# DISPC_L4_PER register map
Vendor: Texas Instruments
Registers are 32-bit, access per field, reset 0x0 unless marked. A register's access mark holds for its fields unless they carry their own. Offsets are as the file gives them; [hi:lo] are bit positions; 'fields as' and 'values as' point back to an identical list.

## DISPC_L4_PER (part 2 of 5)
0x00 DISPC_REVISION ro reset not defined — IP Revision
  [31:0] REVISION — IP revision
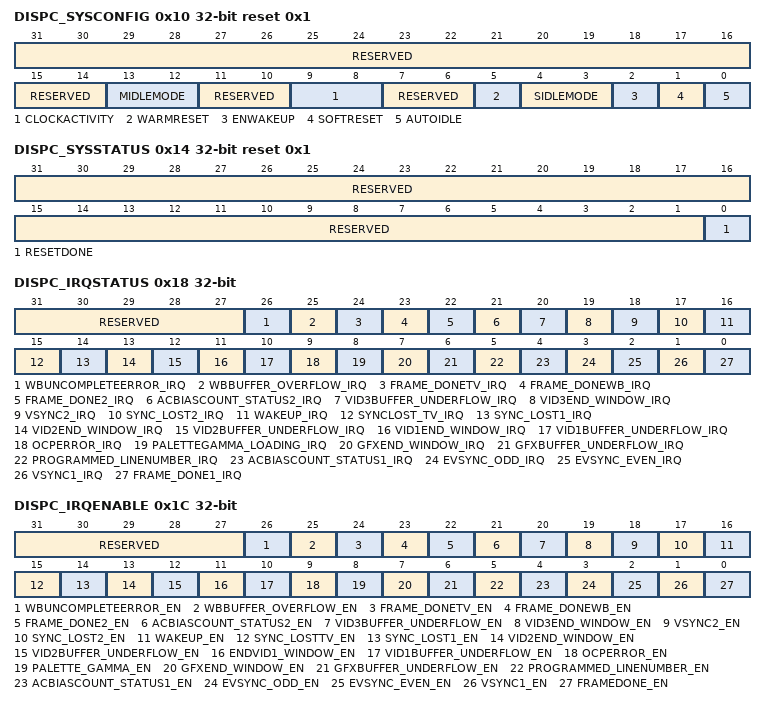
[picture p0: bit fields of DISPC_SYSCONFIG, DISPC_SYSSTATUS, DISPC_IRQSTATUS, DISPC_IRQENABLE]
0x10 DISPC_SYSCONFIG reset 0x1 — This register allows to control various parameters of the OCP interface.
  [31:14] RESERVED ro — Write 0s for future compatibility. Reads returns 0
  [13:12] MIDLEMODE rw — Master interface power management, standby/wait control
    0=Force-standby. MStandby is only asserted when the module is disabled. MStandby is only asserted when the module is disabled.; 1=No-Standby: MStandby is never asserted; 2=Smart-Standby. MStandby is asserted based on the internal activity of the module
  [11:10] RESERVED ro — Write 0s for future compatibility. Reads returns 0
  [9:8] CLOCKACTIVITY rw — Clocks activity during wake up mode period
    0=OCP and Functional clocks can be switched off; 1=Functional clocks can be switched off and OCP clocks are maintained during wake up period; 2=OCP clocks can be switched off and Functional clocks are maintained during wake up period; 3=OCP and Functional clocks are maintained during wake up period
  [7:6] RESERVED ro — Write 0s for future compatibility. Reads returns 0
  [5] WARMRESET rw — Warm reset. Set this bit to 1 triggers a module warm reset. The bit is automatically reset by the hardware. During reads, it always returns 0. The warm reset keep the configuration registers unchanged.
    0=Normal mode; 1=the warmreset is set
  [4:3] SIDLEMODE rw — Slave interface power management, Idle req/ack control
    0=Force-idle. An idle request is acknowledged unconditionally; 1=No-idle. An idle request is never acknowledged; 2=Smart-idle. Acknowledgment to an idle request is given based on the internal activity of the module.
  [2] ENWAKEUP rw — WakeUp feature control
    0=Wakeup is disabled; 1=Wakeup is enabled
  [1] SOFTRESET rw — Software reset. Set this bit to 1 to trigger a module reset. The bit is automatically reset by the hardware. During reads, it always returns 0.
    0=Normal mode; 1=The module is reset
  [0] AUTOIDLE rw — Internal OCP clock gating strategy
    0=OCP clock is free-running; 1=Automatic OCP L3 and L4 clocks gating strategy is applied, based on the OCP interface activity. Automatic functional clock gating is also applied to the functional clock based on the module activity (for instance DISPC_<pipe>_ATTRIBUTES.ENABLE)
0x14 DISPC_SYSSTATUS ro reset 0x1 — This register provides status information about the module, excluding the interrupt status information.
  [31:1] RESERVED — Write 0s for future compatibility. Reads return 0.
  [0] RESETDONE — Internal reset monitoring
    0=RESETDONE_0_r (Internal module reset is on-going); 1=RESETDONE_1_r (Reset completed)
0x18 DISPC_IRQSTATUS access not given — This register regroups all the status of the module internal events that generate an interrupt. Write 1 to a given bit resets this bit
  [31:27] RESERVED ro — Write 0s for future compatibility. Reads returns 0
  [26] WBUNCOMPLETEERROR_IRQ — Write-back DMA buffer is flushed before it is completely drained. In WB capture mode, if the new frame starts before the WB DMA buffers are fully drained (onto external memory), then the contents of the WB DMA buffers are lost (implying last few pixels/lines are corrupted in the captured frame in memory). This interrupt is an indication of that case and will trigger every frame.0x0 READS: Event is false. . 0x0 WRITES: Status bit unchanged. . 0x1 READS: Event is true (Pending). . 0x1 WRITES: Status bit is reset. . (access RW W1toClr)
  [25] WBBUFFER_OVERFLOW_IRQ — Write-back DMA Buffer Overflow. The DMA buffer is full. (access RW W1toClr)
    0=READS: Event is false. WRITES: Status bit unchanged.; 1=READS: Event is true (pending). WRITES: Status bit is reset.
  [24] FRAME_DONETV_IRQ — Frame Done for the TV. The TV output has been disabled by user. All the data have been sent. (access RW W1toClr)
    values as WBBUFFER_OVERFLOW_IRQ
  [23] FRAME_DONEWB_IRQ — Frame Done for the write-back channel. The write-back channel has output the frame. All the data of the frame have been sent to the memory. There is no pending data inside the DMA engine for the write-back channel to be transferred to memory. It is available only when the write-back pipeline transfers back to memory the output of one of the pipelines. In case of overlay capture, the interrupt is not generated and the user shall use the FrameDone for the corresponding captured output. (access RW W1toClr)
    values as WBBUFFER_OVERFLOW_IRQ
  [22] FRAME_DONE2_IRQ — Frame Done for the secondary LCD. The secondary LCD output has been disabled by user. All the data have been sent. (access RW W1toClr)
    values as WBBUFFER_OVERFLOW_IRQ
  [21] ACBIASCOUNT_STATUS2_IRQ — AC Bias Count Status for the secondary LCD (access RW W1toClr)
    values as WBBUFFER_OVERFLOW_IRQ
  [20] VID3BUFFER_UNDERFLOW_IRQ — Video 3 DMA Buffer Underflow. The DMA buffer is not necessarily empty but required data are not present in the DMA buffer (due to out of order responses) (access RW W1toClr)
    values as WBBUFFER_OVERFLOW_IRQ
  [19] VID3END_WINDOW_IRQ — The end of the video 3 Window has been reached. It is detected by the overlay manager when the full video 3 has been displayed. (access RW W1toClr)
    values as WBBUFFER_OVERFLOW_IRQ
  [18] VSYNC2_IRQ — Vertical Synchronization for the secondary LCD (access RW W1toClr)
    values as WBBUFFER_OVERFLOW_IRQ
  [17] SYNC_LOST2_IRQ — Synchronization Lost on the secondary LCD output. The required data are not output at the correct time due to too short blanking periods or stall of at least one pipelines associated with the secondary LCD output. (access RW W1toClr)
    values as WBBUFFER_OVERFLOW_IRQ
  [16] WAKEUP_IRQ — Wake-up (access RW W1toClr)
    values as WBBUFFER_OVERFLOW_IRQ
  [15] SYNCLOST_TV_IRQ — Synchronization Lost on the TV output. The required data are not output at the correct time due to too short blanking periods or stall of at least one pipelines associated with the TV output. (access RW W1toClr)
    values as WBBUFFER_OVERFLOW_IRQ
  [14] SYNC_LOST1_IRQ — Synchronization Lost on the primary LCD output. The required data are not output at the correct time due to too short blanking periods or stall of at least one pipelines associated with the primary LCD output. (access RW W1toClr)
    values as WBBUFFER_OVERFLOW_IRQ
  [13] VID2END_WINDOW_IRQ — The end of the video 2 Window has been reached. It is detected by the overlay manager when the full video 2 has been displayed. (access RW W1toClr)
    values as WBBUFFER_OVERFLOW_IRQ
  [12] VID2BUFFER_UNDERFLOW_IRQ — Video 2 DMA Buffer Underflow. The DMA buffer is not necessarily empty but required data are not present in the DMA buffer (due to out of order responses) (access RW W1toClr)
    values as WBBUFFER_OVERFLOW_IRQ
  [11] VID1END_WINDOW_IRQ — The end of the video 1 Window has been reached. It is detected by the overlay manager when the full video 1 has been displayed. (access RW W1toClr)
    values as WBBUFFER_OVERFLOW_IRQ
  [10] VID1BUFFER_UNDERFLOW_IRQ — Video 1 DMA Buffer Underflow. The DMA buffer is not necessarily empty but required data are not present in the DMA buffer (due to out of order responses) (access RW W1toClr)
    values as WBBUFFER_OVERFLOW_IRQ
  [9] OCPERROR_IRQ — OCP Error. L3 Interconnect has sent SResp=ERR. (access RW W1toClr)
    values as WBBUFFER_OVERFLOW_IRQ
  [8] PALETTEGAMMA_LOADING_IRQ — Palette Gamma Loading status. The palette used as Color Look Up Table (CLUT) for the graphics BITMAP formats (1-, 2-, 4-, or 4-bpp) or as gamma table for the overlay output for the primary LCD output has been loaded successfully. (access RW W1toClr)
    values as WBBUFFER_OVERFLOW_IRQ
  [7] GFXEND_WINDOW_IRQ — The end of the graphics Window has been reached. It is detected by the overlay manager when the full graphics has been displayed. (access RW W1toClr)
    values as WBBUFFER_OVERFLOW_IRQ
  [6] GFXBUFFER_UNDERFLOW_IRQ — Graphics DMA Buffer Underflow. The DMA buffer is not necessarily empty but required data are not present in the DMA buffer (due to out of order responses) (access RW W1toClr)
    values as WBBUFFER_OVERFLOW_IRQ
  [5] PROGRAMMED_LINENUMBER_IRQ — Programmed Line Number. It indicates that the scan of the primary LCD has reached the programmed user line number. (access RW W1toClr)
    values as WBBUFFER_OVERFLOW_IRQ
  [4] ACBIASCOUNT_STATUS1_IRQ — AC Bias Count Status for the primary LCD (access RW W1toClr)
    values as WBBUFFER_OVERFLOW_IRQ
  [3] EVSYNC_ODD_IRQ — VSYNC for odd field from the TV encoder (VENC or HDMI) (access RW W1toClr)
    values as WBBUFFER_OVERFLOW_IRQ
  [2] EVSYNC_EVEN_IRQ — VSYNC for even field from the TV encoder (VENC or HDMI) (access RW W1toClr)
    values as WBBUFFER_OVERFLOW_IRQ
  [1] VSYNC1_IRQ — Vertical Synchronization for the primary LCD. (access RW W1toClr)
    values as WBBUFFER_OVERFLOW_IRQ
  [0] FRAME_DONE1_IRQ — Frame Done for the primary LCD. The primary LCD output has been disabled by user. All the data have been sent. (access RW W1toClr)
    values as WBBUFFER_OVERFLOW_IRQ
0x1C DISPC_IRQENABLE — This register allows to mask/unmask the module internal sources of interrupt, on an event-by-event basis
  [31:27] RESERVED ro — Write 0s for future compatibility. Reads returns 0
  [26] WBUNCOMPLETEERROR_EN rw — The write back buffer has been flushed before it has been fully drained. Enable.
    0=Interrupt is masked; 1=Interrupt is enabled
  [25] WBBUFFER_OVERFLOW_EN rw — Write-back DMA Buffer Overflow. The DMA buffer is full
    0=WBBufferOverflow is masked; 1=WBBufferOverflow generates an interrupt when it occurs
  [24] FRAME_DONETV_EN rw — Frame Done for the TV. The TV output has been disabled by user. All the data have been sent.
    0=Frame Done for the TV output is masked; 1=Frame Done for the TV output generates an interrupt when it occurs
  [23] FRAME_DONEWB_EN rw — Frame Done for the write-back channel. The write-back channel has output the frame. All the data have been sent for the frame have been sent to the memory. There is no pending data inside the DMA engine for the write-back channel to be transferred to memory.
    0=Frame Done for the write-back is masked; 1=Frame Done for the write-back generates an interrupt when it occurs
  [22] FRAME_DONE2_EN rw — Frame Done for the secondary LCD. The secondary LCD output has been disabled by user. All the data have been sent.
    0=Frame Done for the secondary LCD is masked; 1=Frame Done for the secondary LCD generates an interrupt when it occurs
  [21] ACBIASCOUNT_STATUS2_EN rw — AC Bias Count Status for the secondary LCD
    0=ACBiasCountStatus for the secondary LCD output is masked; 1=ACBiasCountStatus for the secondary LCD output generates an interrupt when it occurs
  [20] VID3BUFFER_UNDERFLOW_EN rw — Video 3 DMA Buffer Underflow. The DMA buffer is not necessary empty but required data are not present in the DMA buffer (due to out of order responses)
    0=Vid3BufferUnderflow is masked; 1=Vid3BufferUnderflow generates an interrupt when it occurs
  [19] VID3END_WINDOW_EN rw — The end of the video 3 Window has been reached. It is detected by the overlay manager when the full video 3 has been displayed.
    0=Vid3EndWindow is masked; 1=Vid3EndWindow generates an interrupt when it occurs
  [18] VSYNC2_EN rw — Vertical Synchronization for the secondary LCD
    0=VSYNC for the secondary LCD output is masked; 1=VSYNC for the secondary LCD output generates an interrupt when it occurs
  [17] SYNC_LOST2_EN rw — Synchronization Lost on the secondary LCD output. The required data are not output at the correct time due to too short blanking periods or stall of at least one pipelines associated with the secondary LCD output.
    0=Synchronization Lost on the secondary LCD output is masked; 1=Synchronization Lost on the secondary LCD output generates an interrupt when it occurs
  [16] WAKEUP_EN rw — Wake Up Mask
    0=WakeUp is masked; 1=WakeUp generates an interrupt when it occurs
  [15] SYNC_LOSTTV_EN rw — Synchronization Lost on the TV output. The required data are not output at the correct time due to too short blanking periods or stall of at least one pipelines associated with the TV output.
    0=Synchronization Lost on the TV output is masked; 1=Synchronization Lost on the TV output generates an interrupt when it occurs
  [14] SYNC_LOST1_EN rw — Synchronization Lost for the primary LCD
    0=SyncLost for the primary LCD output is masked; 1=SyncLost for the primary LCD output generates an interrupt when it occurs
  [13] VID2END_WINDOW_EN rw — The end of the video 2 Window has been reached. It is detected by the overlay manager when the full video 2 has been displayed.
    0=Vid2EndWindow is masked; 1=Vid2EndWindow generates an interrupt when it occurs
  [12] VID2BUFFER_UNDERFLOW_EN rw — Video 2 DMA Buffer Underflow. The DMA buffer is not necessary empty but required data are not present in the DMA buffer (due to out of order responses)
    0=Vid2BufferUnderflow is masked; 1=Vid2BufferUnderflow generates an interrupt when it occurs
  [11] ENDVID1_WINDOW_EN rw — The end of the video 1 Window has been reached. It is detected by the overlay manager when the full video 1 has been displayed.
    0=EndVid1Window is masked; 1=EndVid1Window generates an interrupt when it occurs
  [10] VID1BUFFER_UNDERFLOW_EN rw — Video 1 DMA Buffer Underflow. The DMA buffer is not necessary empty but required data are not present in the DMA buffer (due to out of order responses)
    0=Vid1BufferUnderflow is masked; 1=Vid1BufferUnderflow generates an interrupt when it occurs
  [9] OCPERROR_EN rw — OCP Error. L3 Interconnect has sent SResp=ERR.
    0=OCPError is masked; 1=OCPError generates an interrupt when it occurs
  [8] PALETTE_GAMMA_EN rw — Palette Gamma Loading mask. The palette used as Color Look Up Table (CLUT) for the graphics BITMAP formats (1-, 2-, 4-, or 4-bpp) or as gamma table for the overlay output for the primary LCD output has been loaded successfully.
    0=PaletteGamma is masked; 1=PaletteGamma generates an interrupt when it occurs
  [7] GFXEND_WINDOW_EN rw — The end of the graphics Window has been reached. It is detected by the overlay manager when the full graphics has been displayed.
    0=GfxEndWindow is masked; 1=GfxEndWindow generates an interrupt when it occurs
  [6] GFXBUFFER_UNDERFLOW_EN rw — Graphics DMA Buffer Underflow. The DMA buffer is not necessarily empty but required data are not present in the DMA buffer (due to out of order responses)
    0=GfxBufferUnderflow is masked; 1=GfxBufferUnderflow generates an interrupt when it occurs
  [5] PROGRAMMED_LINENUMBER_EN rw — Programmed Line Number. It indicates that the scan of the primary LCD has reached the programmed user line number.
    0=ProgrammedLineNumber is masked; 1=ProgrammedLineNumber generates an interrupt when it occurs
  [4] ACBIASCOUNT_STATUS1_EN rw — AC Bias Count Status for the primary LCD
    0=ACBiasCountStatus for the primary LCD output is masked; 1=ACBiasCountStatus for the primary LCD output generates an interrupt when it occurs
  [3] EVSYNC_ODD_EN rw — VSYNC for odd field from the TV encoder (VENC or HDMI)
    0=EVSYNC_ODD for the TV output is masked; 1=EVSYNC_ODD for the TV output generates an interrupt when it occurs
  [2] EVSYNC_EVEN_EN rw — VSYNC for even field from the TV encoder (VENC or HDMI)
    0=EVSYNC_EVEN for the TV output is masked; 1=EVSYNC_EVEN for the TV output generates an interrupt when it occurs
  [1] VSYNC1_EN rw — Vertical Synchronization for the primary LCD.
    0=VSYNC for the primary LCD output is masked; 1=VSYNC for the primary LCD output generates an interrupt when it occurs
  [0] FRAMEDONE_EN rw — Frame Done for the primary LCD. The primary LCD output has been disabled by user. All the data have been sent.
    0=FrameDone for the primary LCD output is masked; 1=FrameDone for the primary LCD output generates an interrupt when it occurs
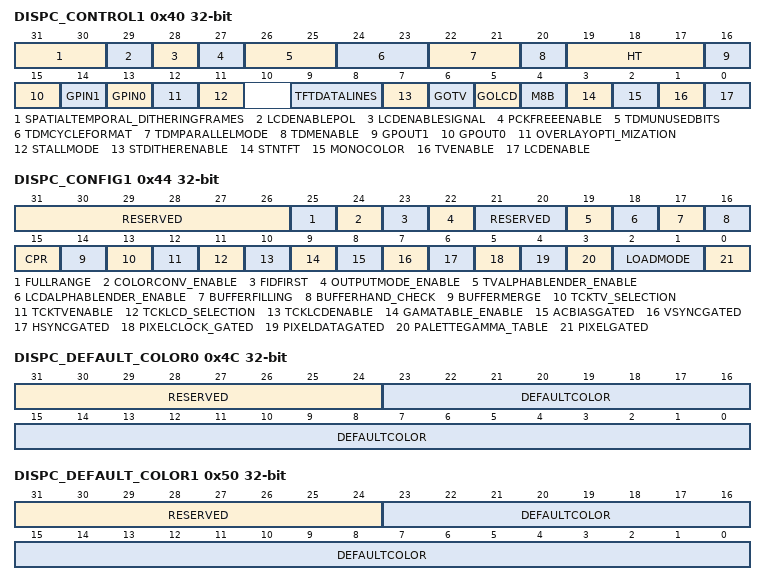
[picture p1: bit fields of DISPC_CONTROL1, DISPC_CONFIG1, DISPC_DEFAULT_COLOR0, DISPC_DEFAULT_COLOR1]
0x40 DISPC_CONTROL1 — The control register configures the Display Controller module for the primary LCD and TV outputs.
  [31:30] SPATIALTEMPORAL_DITHERINGFRAMES rw — Spatial/Temporal dithering number of frames for the primary LCD output wr: VFP start period of primary LCD
    0=Spatial only; 1=Spatial and temporal over 2 frames; 2=Spatial and temporal over 4 frames
  [29] LCDENABLEPOL ro — Write 0s for future compatibility. Reads return 0.
  [28] LCDENABLESIGNAL ro — Write 0s for future compatibility. Reads return 0.
  [27] PCKFREEENABLE ro — Write 0s for future compatibility. Reads return 0.
  [26:25] TDMUNUSEDBITS rw — State of unused bits (TDM mode only) for the primary LCD output. wr: VFP start period of primary LCD
    0=low level (0); 1=high level (1); 2=unchanged from previous state
  [24:23] TDMCYCLEFORMAT rw — Cycle format (TDM mode only) for the primary LCD output wr: VFP start period of primary LCD
    0=1 cycle for 1 pixel; 1=2 cycles for 1 pixel; 2=3 cycles for 1 pixel; 3=3 cycles for 2 pixels
  [22:21] TDMPARALLELMODE rw — Output Interface width (TDM mode only) for the primary LCD output wr: VFP start period of primary LCD
    0=8-bit parallel output interface selected; 1=9-bit parallel output interface selected; 2=12-bit parallel output interface selected; 3=16-bit parallel output interface selected
  [20] TDMENABLE rw — Enable the multiple cycle format (TDM mode only used for TFT mode with the RFBI enable bit off) for the primary LCD output. wr: VFP start period of primary LCD
    0=TDM disabled; 1=TDM enabled
  [19:17] HT rw — Hold Time for TV output wr: EVSYNC Encoded value (from 1 to 8) to specify the number of external digital clock periods to hold the data (programmed value = value minus 1)
  [16] GPOUT1 rw — General Purpose Output Signal wr:immediate
    0=The GPout1 is reset; 1=The GPout1 is set
  [15] GPOUT0 rw — General Purpose Output Signal wr:immediate
    0=The GPout0 is reset; 1=The GPout0 is set
  [14] GPIN1 ro — General Purpose Input Signal wr: immediately
    0=GPIN1_0_r (The GPin1 has been reset); 1=GPIN1_1_r (The GPin1 has been set)
  [13] GPIN0 ro — General Purpose Input Signal wr: immediately
    0=GPIN0_0_r (The GPin0 has been reset); 1=GPIN0_1_r (The GPin0 has been set)
  [12] OVERLAYOPTI_MIZATION rw — Overlay Optimization for the primary LCD output wr: VFP start period of the primary LCD
    0=All the data for all the enabled pipelines are fetched from memory regardless of the overlay/alpha blending configuration; 1=The data not used by the overlay manager because of overlap between layers with no alpha blending between them shall not be fetched from memory in order to optimize the bandwidth
  [11] STALLMODE rw — STALL Mode for the primary LCD output wr: VFP start period of primary LCD
    0=Normal mode selected; 1=STALL mode selected. The Display Controller sends the data without considering the VSYNC/HSYNC. The LCD output is disabled at the end of the transfer of the frame. The S/W has to re-enable the LCD output in order to generate a new frame. The stall mode is used in RFBI and DSI command modes.
  [9:8] TFTDATALINES rw — Number of lines of the primary LCD interface wr: VFP start period of primary LCD
    0=12-bit output aligned on the LSB of the pixel data interface; 1=16-bit output aligned on the LSB of the pixel data interface; 2=18-bit output aligned on the LSB of the pixel data interface; 3=24-bit output aligned on the LSB of the pixel data interface
  [7] STDITHERENABLE rw — Spatial Temporal dithering enable for the primary LCD output wr: VFP start period of primary LCD
    0=Spatial/Temporal dithering logic disabled; 1=Spatial/Temporal dithering logic enabled
  [6] GOTV rw — GO Command for the TV output. It is used to synchronized the pipelines (graphics and/or video ones) associated with the TV output. wr: immediate
    0=The hardware has finished updating the internal shadow registers of the pipeline(s) associated with the TV output using the user values. The hardware resets the bit when the update is completed.; 1=The user has finished to program the shadow registers of the pipeline(s) associated with the TV output and the hardware can update the internal registers at the external VSYNC
  [5] GOLCD rw — GO Command for the primary LCD output. It is used to synchronized the pipelines (graphics and/or video ones) associated with the primary LCD output. wr: immediate
    0=The hardware has finished updating the internal shadow registers of the pipeline(s) connected to the LCD output using the user values. The hardware resets the bit when the update is completed.; 1=The user has finished to program the shadow registers of the pipeline(s) associated with the LCD output and the hardware can update the internal registers at the VFP start period
  [4] M8B rw — Mono 8-bit mode of the primary LCD wr: VFP start period of primary LCD output
    0=Pixel data [3:0] is used to output four pixel values to the panel at each pixel clock transition. (only in Passive Mono 4-bit mode).; 1=Pixel data [7:0] is used to output eight pixel values to the panel each pixel clock transition. (only in Passive Mono 8-bit mode).
  [3] STNTFT rw — LCD Display type of the primary LCD wr: VFP start period of primary LCD output
    0=Passive or STN display operation enabled. STN dither logic is enabled.; 1=Active or TFT display operation enabled. STN Dither logic and output FIFO bypassed.
  [2] MONOCOLOR rw — Monochrome/Color selection for the primary LCD wr: VFP start period of primary LCD output
    0=Color operation enabled (STN mode only); 1=Monochrome operation enabled (STN mode only)
  [1] TVENABLE rw — Enable the TV output wr: immediate effect only occurs at the end of the current frame.
    0=TV output disabled (at the end of the current field if interlace output when the bit is reset); 1=TV output enabled
  [0] LCDENABLE rw — Enable the primary LCD outputs wr: immediate Effect only occurs at the end of the current frame
    0=LCD output disabled (at the end of the frame when the bit is reset); 1=LCD output enabled
0x44 DISPC_CONFIG1 — The control register configures the Display Controller module for the primary LCD output and TV output. Shadow register, updated on VFP start period of primary LCD or EVSYNC or when.GOWB is set to 1 by software and current WB frame is finished (no more data in the write-back pipeline). The synchronization event is defined based on the output using the pipeline: primary LCD, secondary LCD, TV output or write-back to the memory
  [31:26] RESERVED ro — Write 0s for future compatibility. Reads return 0.
  [25] FULLRANGE rw — Color Space Conversion full range setting. wr: VFP start of primary LCD
    0=Limited range selected; 1=Full range selected
  [24] COLORCONV_ENABLE rw — Enable the color space conversion. It shall be reset when CPR bit field is set to 0x1. wr: VFP start of primary LCD
    0=Disable Color Space Conversion RGB to YUV; 1=Enable Color Space Conversion RGB to YUV
  [23] FIDFIRST rw — Selects the first field to output in case of interlace mode. In case of progressive mode, the value is not used. wr: VFP start of primary LCD
    0=First field is even; 1=Odd field is first
  [22] OUTPUTMODE_ENABLE rw — Selects between progressive and interlace mode for the primary LCD output. wr: VFP start of primary LCD
    0=Progressive mode selected; 1=Interlace mode selected
  [21:20] RESERVED rw — Write 0s for future compatibility. Reads return 0.
  [19] TVALPHABLENDER_ENABLE rw — Selects the alpha blender overlay manager for the TV output instead of the color key alpha blender (LCD output). The bit field is deprecated. It is present for software backward compatibility only. When it is enabled, the Z-order defined in each ATTRIBUTES registers for only the pipelines associated pipeline connected to the TV output are invalid and replaced by the following: graphics z-order = 3, video3 z-order = 2, video2 z-order =1 and video1 z-order=0 If it disabled, the z-order and z-order enable bit fields defined in each ATTRIBUTES register are used. wr: EVSYNC start of primary LCD
    0=Alpha blender is disabled; 1=The alpha blender is enabled
  [18] LCDALPHABLENDER_ENABLE rw — Selects the alpha blender overlay manager for the primary LCD output instead of the color key alpha blender (LCD output). The bit field is deprecated. It is present for software backward compatibility only. When it is enabled, the Z-order defined in each ATTRIBUTES registers for only the pipelines associated with the primary LCD output are invalid and replaced by the following: graphics z-order = 3, video3 z-order = 2, video2 z-order =1 and video1 z-order=0 If it disabled, the z-order and z-order enable bit fields defined in each ATTRIBUTES register are used. wr: VFP start of primary LCD
    0=Alpha blender is disabled. The color key alpha blending is used.; 1=The alpha blender is enabled
  [17] BUFFERFILLING rw — Controls if the DMA buffers are refilled only when the LOW threshold is reached or if all DMA buffers are refilled when at least one of them reaches the LOW threshold. wr: immediate
    0=Each DMA buffer is refilled when it reaches LOW threshold; 1=All DMA buffers are refilled up to high threshold when at least one of them reaches the LOW threshold. (only active DMA buffers shall be considered and when reaching the end of the frame the DMA buffer goes to empty condition so no need to fill it again).
  [16] BUFFERHAND_CHECK rw — Controls the handcheck between DMA buffer and STALL signal in order to prevent from underflow. The bit shall be set to 0 when the module is not in STALL mode. (primary LCD output) wr: VFP start of primary LCD
    0=Only the STALL signal (generated by RFBI, DSI1 or DSI2 depending on which IP uses the LCD output) is used regardless of the DMA buffer fullness information in order to provide data to the RFBI,DSI1 or DS2 module; 1=The STALL signal (generated by RFBI, DSI1 or DSI2 depending on which IP uses the LCD output) is used in combination with the DMA buffer fullness information in order to provide data to the RFBI, DSI1 or DSI2 module only when it does not generated buffer underflow
  [15] CPR rw — Color Phase Rotation Control (primary LCD output). It shall be reset when ColorConvEnable bit field is set to 1 wr: VFP start period of primary LCD output
    0=Color Phase Rotation Disabled; 1=Color Phase Rotation Enabled
  [14] BUFFERMERGE rw — Buffer merge control wr: EVSYNC or whenDISPC_CONTROL2.GOWB is set to 1 by software and current WB frame is finished (no more data in the write-back pipeline). The synchronization event is defined based on the output using the pipeline: primary LCD, secondary LCD, TV output or write-back to the memory or VFP When enabled, the DISPC_GLOBAL_BUFFER register is ignored. This bit must be set to zero when the write back channel is used. When DISPC_CONTROL2.GOWB is used BUFFERMERGE MUST be zero. When DISPC_CONTROL2.GOWB is used BUFFERMERGE MUST be zero. wr: immediate
    0=DMA buffer merge disabled Each DMA buffer is dedicated to one pipeline; 1=DMA buffer merge enabled All the DMA buffers are merged into a single one to be used by the single active pipeline
  [13] TCKTV_SELECTION rw — Transparency Color Key Selection (TV output) wr: EVSYNC
    0=Destination transparency color key selected; 1=Source transparency color key selected
  [12] TCKTVENABLE rw — Transparency Color Key Enabled (TV output) wr: EVSYNC
    0=Disable the transparency color key for the TV output; 1=Enable the transparency color key for the TV output
  [11] TCKLCD_SELECTION rw — Transparency Color Key Selection (primary LCD output) wr: VFP start period of primary LCD output
    values as TCKTV_SELECTION
  [10] TCKLCDENABLE rw — Transparency Color Key Enabled (primary LCD output) wr: VFP start period of primary LCD output
    0=Disable the transparency color key for the LCD; 1=Enable the transparency color key for the LCD
  [9] GAMATABLE_ENABLE rw — For backward compatibility, an enable bit has been added on the 2 additional gamma tables (secondary display and TV). Gamma table of LCD1 is always enabled.
    0=Gamma table LDC2 and TV are bypassed; 1=Gamma table LCD2 and TV are enabled
  [8] ACBIASGATED rw — ACBias Gated Enabled (primary LCD output) wr: VFP start period of primary LCD output
    0=AcBias Gated Disabled; 1=AcBias Gated Enabled
  [7] VSYNCGATED rw — VSYNC Gated Enabled (primary LCD output) wr: VFP start period of primary LCD output
    0=VSYNC Gated Disabled; 1=VSYNC Gated Enabled
  [6] HSYNCGATED rw — HSYNC Gated Enabled (primary LCD output) wr: VFP start period of primary LCD output
    0=HSYNC Gated Disabled; 1=HSYNC Gated Enabled
  [5] PIXELCLOCK_GATED rw — Pixel Clock Gated Enabled (primary LCD output) wr: VFP start period of primary LCD output
    0=Pixel Clock Gated Disabled; 1=Pixel Clock Gated Enabled
  [4] PIXELDATAGATED rw — Pixel Data Gated Enabled (primary LCD output) wr: VFP start period of primary LCD output
    0=Pixel Data Gated Disabled; 1=Pixel Data Gated Enabled
  [3] PALETTEGAMMA_TABLE rw — Palette/Gamma Table selection wr: VFP start period of primary LCD output or VFP start period of secondary LCD output or EVSYNC or whenDISPC_CONTROL2.GOWB is set to 1 by software and current WB frame is finished (no more data in the write-back pipeline). The synchronization event is defined based on the output using the graphics pipeline: primary LCD, secondary LCD, TV output or write-back to the memory. In case of the table is used as gamma table, it is used for the primary LCD output only.
    0=LUT used as palette (only if graphics format is BITMAP1, 2, 4, and 8); 1=LUT used as gamma table (only if graphics format is NOT BITMAP1, 2, 4, and 8 or no graphics window present)
  [2:1] LOADMODE rw — Loading Mode for the Palette/Gamma Table wr: VFP start period of primary LCD output or VFP start period of secondary LCD output or EVSYNC or whenDISPC_CONTROL2.GOWB is set to 1 by software and current WB frame is finished (no more data in the write-back pipeline). The synchronization event is defined based on the output using the pipeline: primary LCD, secondary LCD, TV output or write-back to the memory
    0=Palette/Gamma Table and data are loaded every frame; 1=Palette/Gamma Table to be loaded. The user sets the bit when the palette/gamma table has to be loaded. Hardware resets the bit to 0x2 when table has been loaded. (.ENABLE has to be set to 1).; 2=Frame data only loaded every frame; 3=Palette/Gamma Table and frame data loaded on first frame then switch to 0x2 (Hardware)
  [0] PIXELGATED rw — Pixel Gated Enable (only for TFT) (primary LCD output) wr: VFP start period of primary LCD output
    0=Pixel clock always toggles (only in TFT mode); 1=Pixel clock only toggles when there is valid data to display. (only in TFT mode)
0x4C DISPC_DEFAULT_COLOR0 — The control register allows to configure the default solid background color for the primary LCD. Shadow register, updated on VFP start period of the primary LCD
  [31:24] RESERVED ro — Write 0s for future compatibility. Reads return 0.
  [23:0] DEFAULTCOLOR rw — 24-bit RGB color value to specify the default solid color to display when there is no data from the overlays.
0x50 DISPC_DEFAULT_COLOR1 — The control register allows to configure the default solid background color for the TV output. Shadow register, updated on EVSYNC
  fields as DISPC_DEFAULT_COLOR0
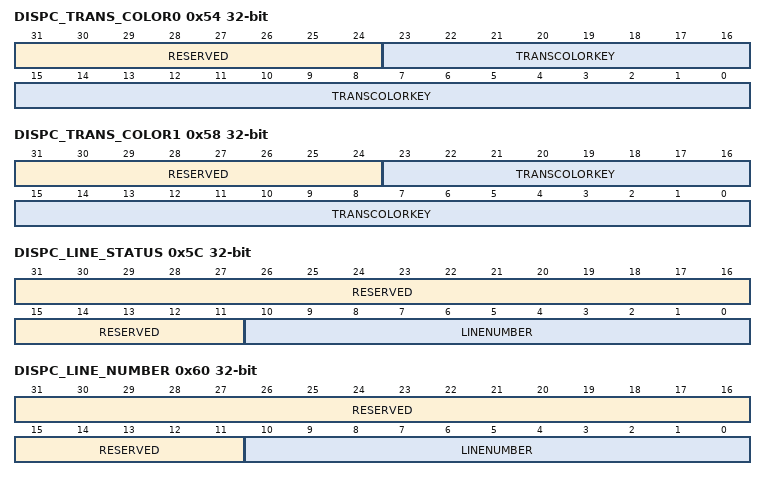
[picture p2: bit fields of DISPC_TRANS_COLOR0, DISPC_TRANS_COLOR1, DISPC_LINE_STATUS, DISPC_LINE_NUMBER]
0x54 DISPC_TRANS_COLOR0 — The register sets the transparency color value for the video/graphics overlays for the primary LCD output. Shadow register, updated on VFP start period of the primary LCD
  [31:24] RESERVED ro — Write 0s for future compatibility. Reads return 0.
  [23:0] TRANSCOLORKEY rw — Transparency Color Key Value in RGB format [0] BITMAP 1 (CLUT), [23,1] set to 0s [1:0] BITMAP 2 (CLUT), [23,2] set to 0s [3:0] BITMAP 4 (CLUT), [23,4] set to 0s [7:0] BITMAP 8 (CLUT), [23,8] set to 0s [11:0] RGB 12, [23,12] set to 0s [15:0] RGB 16, [23,16] set to 0s [23:0] RGB 24
0x58 DISPC_TRANS_COLOR1 — The register sets the transparency color value for the video/graphics overlays for the TV output. Shadow register, updated on EVSYNC
  fields as DISPC_TRANS_COLOR0
0x5C DISPC_LINE_STATUS ro — The control register indicates the current primary LCD panel display line number.
  [31:11] RESERVED — Write 0s for future compatibility. Reads return 0.
  [10:0] LINENUMBER — Current LCD panel line number Current display line number. The first active line has the value 0. During blanking lines the line number is not incremented.
0x60 DISPC_LINE_NUMBER — The control register indicates the primary LCD panel display line number for the interrupt and the DMA request. Shadow register, updated on VFP start period of primary LCD.
  [31:11] RESERVED ro — Write 0s for future compatibility. Reads return 0.
  [10:0] LINENUMBER rw — LCD panel line number programming LCD line number defines the line on which the programmable interrupt is generated and the DMA request occurs.
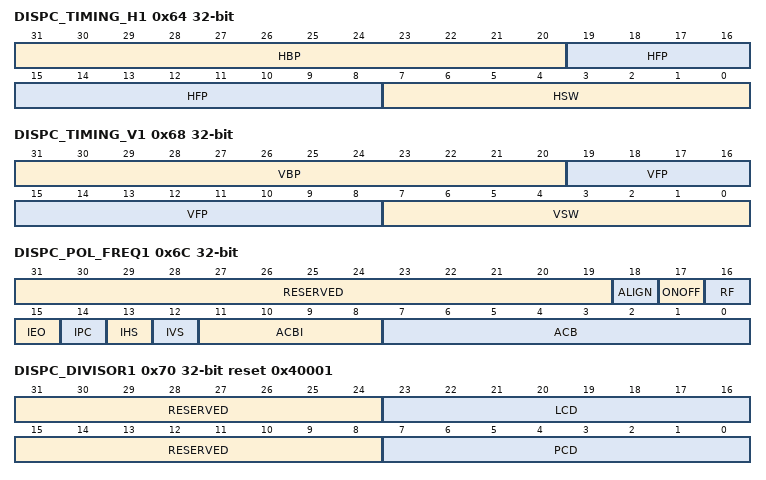
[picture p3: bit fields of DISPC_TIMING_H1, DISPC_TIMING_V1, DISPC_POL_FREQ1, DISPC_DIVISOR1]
0x64 DISPC_TIMING_H1 rw — The register configures the timing logic for the HSYNC signal. It is used for the primary LCD output. Shadow register, updated on VFP start period of primary LCD
  [31:20] HBP — Horizontal Back Porch. Encoded value (from 1 to 4096) to specify the number of pixel clock periods to add to the beginning of a line transmission before the first set of pixels is output to the display (program to value minus 1). When in BT mode and interlaced, this field corresponds to the vertical field blanking No 2 for Even Field.
  [19:8] HFP — Horizontal front porch. Encoded value (from 1 to 4096) to specify the number of pixel clock periods to add to the end of a line transmission before line clock is asserted (program to value minus 1). When in BT mode and interlaced, this field corresponds to the vertical field blanking No 1 for Even Field.
  [7:0] HSW — Horizontal synchronization pulse width Encoded value (from 1 to 256) to specify the number of pixel clock periods to pulse the line clock at the end of each line (program to value minus 1). When in BT mode, this field corresponds to the horizontal blanking
0x68 DISPC_TIMING_V1 rw — The register configures the timing logic for the VSYNC signal. It is used for the primary LCD output. Shadow register, updated on VFP start period of primary LCD
  [31:20] VBP — Vertical back porch Encoded value (from 0 to 4095) to specify the number of line clock periods to add to the beginning of a frame.
  [19:8] VFP — Vertical front porch Encoded value (from 0 to 4095) to specify the number of line clock periods to add to the end of each frame.
  [7:0] VSW — Vertical synchronization pulse width In active mode, encoded value (from 1 to 256) to specify the number of line clock periods (program to value minus 1) to pulse the frame clock (VSYNC) pin at the end of each frame after the end of frame wait (VFP) period elapses. Frame clock uses as VSYNC signal in active mode. In passive mode, encoded value (from 1 to 256) to specify the number of extra line clock periods (program to value minus 1) to insert after the vertical front porch (VFP) period has elapsed.
0x6C DISPC_POL_FREQ1 — The register configures the signal configuration. It is used for the primary LCD output. Shadow register, updated on VFP start period of primary LCD.
  [31:19] RESERVED ro — Write 0s for future compatibility. Reads return 0.
  [18] ALIGN rw — Defines the alignment between HSYNC and VSYNC assertion.
    0=VSYNC and HSYNC are not aligned; 1=VSYNC and HSYNC assertions are aligned
  [17] ONOFF rw — HSYNC/VSYNC Pixel clock Control On/Off
    0=HSYNC and VSYNC are driven on opposite edges of pixel clock than pixel data; 1=HSYNC and VSYNC are driven according to bit 16
  [16] RF rw — Program HSYNC/VSYNC Rise or Fall
    0=HSYNC and VSYNC are driven on falling edge of pixel clock (if bit 17 set to 1); 1=HSYNC and VSYNC are driven on rising edge of pixel clock (if bit 17 set to 1)
  [15] IEO rw — Invert output enable
    0=Ac-bias is active high (active display mode); 1=Ac-bias is active low (active display mode)
  [14] IPC rw — Invert pixel clock
    0=Data is driven on the LCD data lines on the rising-edge of the pixel clock; 1=Data is driven on the LCD data lines on the falling-edge of the pixel clock
  [13] IHS rw — Invert HSYNC
    0=Line clock pin is active high and inactive low; 1=Line clock pin is active low and inactive high
  [12] IVS rw — Invert VSYNC
    0=Frame clock pin is active high and inactive low; 1=Frame clock pin is active low and inactive high
  [11:8] ACBI rw — AC Bias Pin transitions per interrupt Value (from 0 to 15) used to specify the number of AC Bias pin transitions
  [7:0] ACB rw — AC Bias Pin Frequency Value (from 0 to 255) used to specify the number of line clocks to count before transitioning the AC Bias pin. This pin is used to periodically invert the polarity of the power supply to prevent DC charge build-up within the display.
0x70 DISPC_DIVISOR1 reset 0x40001 — The register configures the divisors. It is used for the primary LCD output Shadow register, updated on VFP start period of primary LCD
  [31:24] RESERVED ro — Write 0s for future compatibility. Reads return 0.
  [23:16] LCD rw — Display Controller Logic Clock Divisor Value (from 1 to 255) to specify the intermediate pixel clock frequency based on the LCD1_CLK. The value 0 is invalid.
  [15:8] RESERVED ro — Write 0s for future compatibility. Reads return 0.
  [7:0] PCD rw — Pixel Clock Divisor Value (from 1 to 255) to specify the frequency of the pixel clock based on the LCD1_CLK divided byDISPC_DIVISOR1.LCD value. The values 0 is invalid.
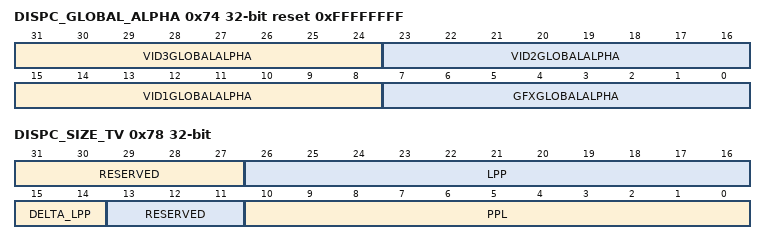
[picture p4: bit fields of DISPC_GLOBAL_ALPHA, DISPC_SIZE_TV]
0x74 DISPC_GLOBAL_ALPHA rw reset 0xFFFFFFFF — The register defines the global alpha value for the graphics and three video pipelines. Shadow register, updated on VFP start period of primary LCD or VFP start period of the secondary LCD or EVSYNC or when.GOWB is set to 1 by software and current WB frame is finished (no more data in the write-back pipeline). The synchronization event is defined based on the output using the pipeline: primary LCD, secondary LCD, TV output or write-back to the memory for each bit field depending on the association of the each pipeline with the primary LCD, secondary LCD or TV output.
  [31:24] VID3GLOBALALPHA — Global alpha value from 0 to 255. 0 corresponds to fully transparent and 255 to fully opaque.
  [23:16] VID2GLOBALALPHA — Global alpha value from 0 to 255. 0 corresponds to fully transparent and 255 to fully opaque.
  [15:8] VID1GLOBALALPHA — Global alpha value from 0 to 255. 0 corresponds to fully transparent and 255 to fully opaque.
  [7:0] GFXGLOBALALPHA — Global alpha value from 0 to 255. 0 corresponds to fully transparent and 255 to fully opaque.
0x78 DISPC_SIZE_TV — The register configures the size of the TV output field (interlace), frame (progressive) (horizontal and vertical). Shadow register, updated on EVSYNC. A delta value is used to indicate if the odd field has same vertical size as the even field or +/- one line.
  [31:27] RESERVED ro — Write 0s for future compatibility. Reads return 0.
  [26:16] LPP rw — Lines per panel (LPP). Encoded value (from 1 to 2048) to specify the number of LPP.
  [15:14] DELTA_LPP rw — Indicates the delta size value of the odd field compared to the even field
    0=Same size; 1=Odd size = Even size +1; 2=Odd size = Even Size -1
  [13:11] RESERVED ro — Write 0s for future compatibility. Reads return 0.
  [10:0] PPL rw — Pixels per line Encoded value (from 1 to 2048) to specify the number of pixels contains within each line on the display.
